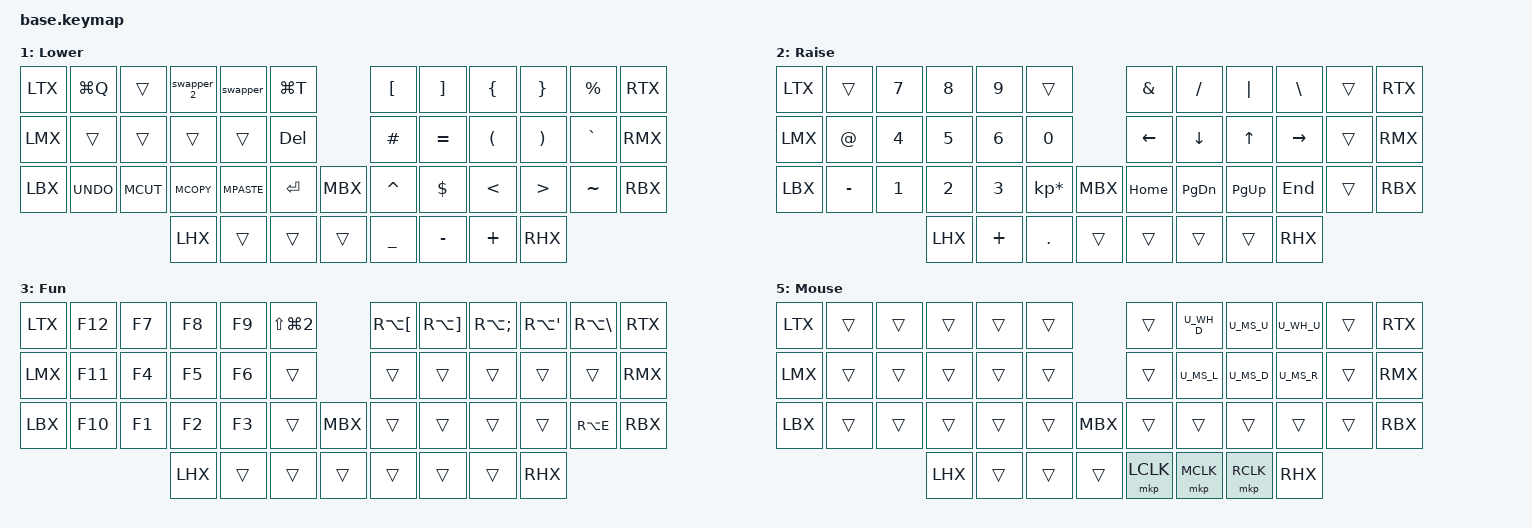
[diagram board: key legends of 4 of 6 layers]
#include <behaviors.dtsi>
#include <dt-bindings/zmk/keys.h>
#include <dt-bindings/zmk/bt.h>
#include <dt-bindings/zmk/ext_power.h>

#define BASE  0
#define LOWER 1
#define RAISE 2
#define FUN   3
#define ADJUST 4
#define MOUSE 5

#include "keys/base.h"
#include "includes/macros.dtsi"
#include "includes/mods.dtsi"
#include "includes/dance.dtsi"
#include "includes/combos.dtsi"
#include "includes/morphs.dtsi"
#include "includes/settings.dtsi"
#include "includes/mouse.dtsi"

#define MEH LC(LS(LALT))
#define MCUT LG(X)
#define MCOPY LG(C)
#define MPASTE LG(V)
#define COMPOSE K_CMENU

/ {
 
  keymap {
    compatible = "zmk,keymap";

    base_layer {
      display-name = "Base";
      bindings = <
//    ╭───┬─────────────┬─────────────┬──────────────┬──────────────┬───────────────╮                                 ╭─────────────────┬──────────────┬──────────────┬─────────────┬──────────────┬───╮
//    │   │      Q      │      W      │  &hml MEH E  │      R       │       T       │                                 │       Y         │      U       │  &hmr MEH I  │      O      │      P       │   │
//    ├───┼─────────────┼─────────────┼──────────────┼──────────────┼───────────────┤                                 ├─────────────────┼──────────────┼──────────────┼─────────────┼──────────────┼───┤
//    │   │ &hml LGUI A │ &hml LALT S │ &hml LCTRL D │ &hml LSHFT F │       G       │                                 │       H         │ &hmr LSHFT J │ &hmr LCTRL K │ &hmr LALT L │ &hmr LGUI '  │   │
//    ├───┼─────────────┼─────────────┼──────────────┼──────────────┼───────────────┼─────────────────────────────────┼─────────────────┼──────────────┼──────────────┼─────────────┼──────────────┼───┤
//    │   │      Z      │      X      │      C       │      V       │       B       │                                 │       N         │      M       │ &comma_morph │ &dot_morph  │ &qmark_morph │   │
//    ╰───┴─────────────┴─────────────┼──────────────┼──────────────┼───────────────┼─────────────────┬───────────────┼─────────────────┼──────────────┼──────────────┼─────────────┴──────────────┴───╯
//                                    │              │ &kp ESC      │ &lt LOWER TAB │ &lt ADJUST BSPC │ &tm RSHFT RET │ &lt RAISE SPACE │ &lt FUN DEL  │              │                                 
//                                    ╰──────────────┴──────────────┴───────────────┴─────────────────┴───────────────┴─────────────────┴──────────────┴──────────────╯                                 
  _LTX   &kp Q         &kp W         &hml MEH E     &kp R          &kp T                                              &kp Y            &kp U          &hmr MEH I     &kp O         &kp P           _RTX
  _LMX   &hml LGUI A   &hml LALT S   &hml LCTRL D   &hml LSHFT F   &kp G                                              &kp H            &hmr LSHFT J   &hmr LCTRL K   &hmr LALT L   &hmr LGUI SQT   _RMX
  _LBX   &kp Z         &kp X         &kp C          &kp V          &kp B                         _MBX                 &kp N            &kp M          &comma_morph   &dot_morph    &qmark_morph    _RBX
                                     _LHX           &kp ESC        &lt LOWER TAB   &lt ADJUST BSPC   &tm RSHFT RET   &lt RAISE SPACE   &lt FUN DEL    _RHX                                             
      >;
    };

    lower_layer {
      display-name = "Lower";
      bindings = <
//    ╭───┬──────┬──────┬───────┬───────┬─────╮       ╭───┬───┬───┬───┬───┬───╮
//    │⌥Q │      │      │       │  ⌥ ⇥  │ ⌥T  │       │ [ │ ] │ { │ } │ % │   │
//    ├───┼──────┼──────┼───────┼───────┼─────┤       ├───┼───┼───┼───┼───┼───┤
//    │   │      │      │       │       │ DEL │       │ # │ = │ ( │ ) │ ` │   │
//    ├───┼──────┼──────┼───────┼───────┼─────┼───────┼───┼───┼───┼───┼───┼───┤
//    │   │  ↩️  │  ✂️  │  📄   │  📋   │ RET │       │ ^ │ $ │ < │ > │ ~ │   │
//    ╰───┴──────┴──────┼───────┼───────┼─────┼───┬───┼───┼───┼───┼───┴───┴───╯
//                      │       │       │     │   │ _ │ - │ + │   │            
//                      ╰───────┴───────┴─────┴───┴───┴───┴───┴───╯            
  _LTX   &kp LG(Q)    &trans       &swapper_2    &swapper      &kp LG(T)                             &kp LBKT    &kp RBKT     &kp LBRC   &kp RBRC   &kp PRCNT   _RTX
  _LMX   &trans       &trans       &trans        &trans        &kp DEL                               &kp HASH    &kp EQUAL    &kp LPAR   &kp RPAR   &kp GRAVE   _RMX
  _LBX   &kp K_UNDO   &kp MCUT     &kp MCOPY     &kp MPASTE    &kp RET               _MBX            &kp CARET   &kp DOLLAR   &kp LT     &kp GT     &kp TILDE   _RBX
                                   _LHX          &trans        &trans      &trans   &kp UNDERSCORE   &kp MINUS   &kp PLUS     _RHX                                  
      >;
    };

    raise_layer {
      display-name = "Raise";
      bindings = <
//    ╭───┬───┬───┬───┬───┬───╮       ╭───┬───┬───┬───┬──────┬───╮
//    │   │   │ 7 │ 8 │ 9 │   │       │ & │ / │ | │ \ │      │   │
//    ├───┼───┼───┼───┼───┼───┤       ├───┼───┼───┼───┼──────┼───┤
//    │   │ @ │ 4 │ 5 │ 6 │ 0 │       │ ← │ ↓ │ ↑ │ → │      │   │
//    ├───┼───┼───┼───┼───┼───┼───────┼───┼───┼───┼───┼──────┼───┤
//    │   │ - │ 1 │ 2 │ 3 │ * │       │ ⇱ │ ⇟ │ ⇞ │ ⇲ │      │   │
//    ╰───┴───┴───┼───┼───┼───┼───┬───┼───┼───┼───┼───┴──────┴───╯
//                │   │ + │ . │   │   │   │   │   │               
//                ╰───┴───┴───┴───┴───┴───┴───┴───╯               
  _LTX   &trans    &kp N7   &kp N8   &kp N9    &trans                              &kp AMPS   &kp FSLH    &kp PIPE    &kp BSLH    &trans     _RTX
  _LMX   &kp AT    &kp N4   &kp N5   &kp N6    &kp N0                              &kp LEFT   &kp DOWN    &kp UP      &kp RIGHT   &trans     _RMX
  _LBX   &kp MINUS &kp N1   &kp N2   &kp N3    &kp KP_MULTIPLY        _MBX         &kp HOME   &kp PG_DN   &kp PG_UP   &kp END     &trans     _RBX
                           _LHX      &kp PLUS  &kp DOT           &trans   &trans   &trans     &trans      _RHX                                   
      >;
    };

    fun_layer {
      display-name = "Fun";
      bindings = <
//    ╭───┬─────┬────┬────┬────┬───────╮       ╭───┬───────┬───────┬──────┬──────┬───╮
//    │   │ F12 │ F7 │ F8 │ F9 │ PSCRN │       │ š │   đ   │   č   │   ć  │   ž  │   │
//    ├───┼─────┼────┼────┼────┼───────┤       ├───┼───────┼───────┼──────┼──────┼───┤
//    │   │ F11 │ F4 │ F5 │ F6 │       │       │   │       │       │      │      │   │
//    ├───┼─────┼────┼────┼────┼───────┼───────┼───┼───────┼───────┼──────┼──────┼───┤
//    │   │ F10 │ F1 │ F2 │ F3 │       │       │   │       │       │      │  €   │   │
//    ╰───┴─────┴────┼────┼────┼───────┼───┬───┼───┼───────┼───────┼──────┴──────┴───╯
//                   │    │    │       │   │   │   │       │       │                  
//                   ╰────┴────┴───────┴───┴───┴───┴───────┴───────╯                  
  _LTX   &kp F12   &kp F7   &kp F8   &kp F9   &kp LS(LG(N2))                     &kp RA(LBKT) &kp RA(RBKT)  &kp RA(SEMI)  &kp RA(SQT)  &kp RA(BSLH)  _RTX
  _LMX   &kp F11   &kp F4   &kp F5   &kp F6   &trans                        &trans       &trans        &trans        &trans       &trans        _RMX
  _LBX   &kp F10   &kp F1   &kp F2   &kp F3   &trans           _MBX         &trans       &trans        &trans        &trans       &kp RA(E)     _RBX
                            _LHX     &trans   &trans      &trans   &trans   &trans       &trans        _RHX                                  
      >;
    };

    adjust_layer {
      display-name = "Adjust";
      bindings = <
//    ╭───┬─────┬─────┬─────┬─────┬─────╮        ╭──────┬──────┬──────┬───┬────┬───╮
//    │   │     │ Sw7 │ Sw8 │ Sw9 │     │        │      │  🔅  │  🔆  │   │    │   │
//    ├───┼─────┼─────┼─────┼─────┼─────┤        ├──────┼──────┼──────┼───┼────┼───┤
//    │   │     │ Sw4 │ Sw5 │ Sw6 │     │        │  🔇  │  🔉  │  🔊  │   │    │   │
//    ├───┼─────┼─────┼─────┼─────┼─────┼────────┼──────┼──────┼──────┼───┼────┼───┤
//    │   │     │ Sw1 │ Sw2 │ Sw3 │ WmP │        │ 🛜   │   🛜 │   🛜 │   │    │   │
//    ╰───┴─────┴─────┼─────┼─────┼─────┼───┬────┼──────┼──────┼──────┼───┴────┴───╯
//                    │     │     │     │   │ ⏯️ │  ⏮️  │  ⏭️  │      │             
//                    ╰─────┴─────┴─────┴───┴────┴──────┴──────┴──────╯             
  _LTX   &trans   &kp LC(RG(N7)) &kp LC(RG(N8))   &kp LC(RG(N9))   &trans                       &trans         &kp C_BRI_DN   &kp C_BRI_UP   &trans   &trans     _RTX
  _LMX   &trans   &kp LC(RG(N4)) &kp LC(RG(N5))   &kp LC(RG(N6))   &trans                       &kp C_MUTE     &kp C_VOL_DN   &kp C_VOL_UP   &trans   &trans     _RMX
  _LBX   &trans   &kp LC(RG(N1)) &kp LC(RG(N2))   &kp LC(RG(N3))   &kp LC(LG(LS(LEFT)))   _MBX  &trans         &trans         &trans         &trans   &trans     _RBX
                                _LHX         &trans       &trans   &trans   &kp C_PP   &kp C_PREV     &kp C_NEXT     _RHX                                      
      >;
    };

    empty_layer {
      display-name = "Mouse";
      bindings = <
//    ╭───┬───┬───┬───┬───┬───╮       ╭───┬───┬───┬───┬───┬───╮
//    │   │   │   │   │   │   │       │   │   │   │   │   │   │
//    ├───┼───┼───┼───┼───┼───┤       ├───┼───┼───┼───┼───┼───┤
//    │   │   │   │   │   │   │       │   │   │   │   │   │   │
//    ├───┼───┼───┼───┼───┼───┼───────┼───┼───┼───┼───┼───┼───┤
//    │   │   │   │   │   │   │       │   │   │   │   │   │   │
//    ╰───┴───┴───┼───┼───┼───┼───┬───┼───┼───┼───┼───┴───┴───╯
//                │   │   │   │   │   │   │   │   │            
//                ╰───┴───┴───┴───┴───┴───┴───┴───╯            
  _LTX   &trans   &trans   &trans   &trans   &trans                     &trans   U_WH_D   U_MS_U   U_WH_U   &trans   _RTX
  _LMX   &trans   &trans   &trans   &trans   &trans                     &trans   U_MS_L   U_MS_D   U_MS_R   &trans   _RMX
  _LBX   &trans   &trans   &trans   &trans   &trans        _MBX         &trans   &trans   &trans   &trans   &trans   _RBX
                           _LHX     &trans   &trans   &trans   &mkp LCLK   &mkp MCLK   &mkp RCLK   _RHX                           
      >;
    };
  };
};
